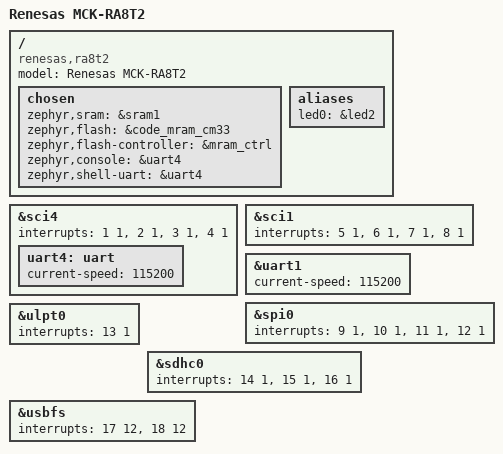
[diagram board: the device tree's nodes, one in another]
/*
 * Copyright (c) 2026 Renesas Electronics Corporation
 * SPDX-License-Identifier: Apache-2.0
 */

/dts-v1/;

#include <renesas/ra/ra8/r7ka8t2lflcac_cm33.dtsi>
#include "mck_ra8t2.dtsi"

/ {
	model = "Renesas MCK-RA8T2";
	compatible = "renesas,ra8t2", "renesas,ra8";

	chosen {
		zephyr,sram = &sram1;
		zephyr,flash = &code_mram_cm33;
		zephyr,flash-controller = &mram_ctrl;
		zephyr,console = &uart4;
		zephyr,shell-uart = &uart4;
	};

	aliases {
		led0 = &led2;
	};
};

&sci4 {
	interrupts = <1 1>, <2 1>, <3 1>, <4 1>;
	interrupt-names = "rxi", "txi", "tei", "eri";
	status = "okay";

	uart4: uart {
		current-speed = <115200>;
		status = "okay";
	};
};

&sci1 {
	interrupts = <5 1>, <6 1>, <7 1>, <8 1>;
	interrupt-names = "rxi", "txi", "tei", "eri";
};

&uart1 {
	current-speed = <115200>;
};

&spi0 {
	interrupts = <9 1>, <10 1>, <11 1>, <12 1>;
	interrupt-names = "rxi", "txi", "tei", "eri";
};

&ulpt0 {
	interrupts = <13 1>;
	interrupt-names = "ulpti";
};

&sdhc0 {
	interrupts = <14 1>, <15 1>, <16 1>;
	interrupt-names = "accs", "card", "dma-req";
};

&usbfs {
	interrupts = <17 12>, <18 12>;
	interrupt-names = "usbfs-i", "usbfs-r";
};
